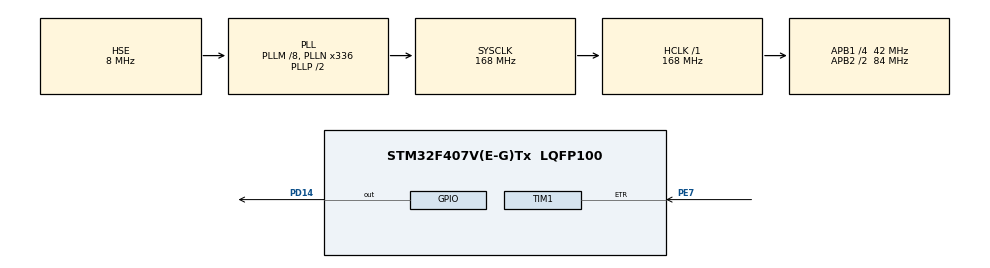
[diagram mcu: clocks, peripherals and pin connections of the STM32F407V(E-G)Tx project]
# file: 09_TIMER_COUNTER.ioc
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Mcu.Family=STM32F4
Mcu.Name=STM32F407V(E-G)Tx
Mcu.Package=LQFP100
NVIC.PriorityGroup=NVIC_PRIORITYGROUP_0
NVIC.TIM1_UP_TIM10_IRQn=true\:0\:0\:false\:false\:true\:true\:true
NVIC.TIM2_IRQn=true\:0\:0\:false\:false\:true\:false\:true
NVIC.TimeBase=TIM2_IRQn
NVIC.TimeBaseIP=TIM2
PA13.Mode=Serial_Wire
PA13.Signal=SYS_JTMS-SWDIO
PA14.Mode=Serial_Wire
PA14.Signal=SYS_JTCK-SWCLK
PD14.Signal=GPIO_Output
PE7.Signal=S_TIM1_ETR
PH0-OSC_IN.Mode=HSE-External-Oscillator
PH0-OSC_IN.Signal=RCC_OSC_IN
PH1-OSC_OUT.Mode=HSE-External-Oscillator
PH1-OSC_OUT.Signal=RCC_OSC_OUT
ProjectManager.HeapSize=0x200
ProjectManager.StackSize=0x400
ProjectManager.TargetToolchain=STM32CubeIDE
RCC.48MHZClocksFreq_Value=48000000
RCC.AHBFreq_Value=168000000
RCC.APB1CLKDivider=RCC_HCLK_DIV4
RCC.APB1Freq_Value=42000000
RCC.APB1TimFreq_Value=84000000
RCC.APB2CLKDivider=RCC_HCLK_DIV2
RCC.APB2Freq_Value=84000000
RCC.APB2TimFreq_Value=168000000
RCC.CortexFreq_Value=168000000
RCC.HCLKFreq_Value=168000000
RCC.HSE_VALUE=8000000
RCC.HSI_VALUE=16000000
RCC.PLLM=8
RCC.PLLN=336
RCC.PLLQ=7
RCC.PLLSourceVirtual=RCC_PLLSOURCE_HSE
RCC.SYSCLKFreq_VALUE=168000000
RCC.SYSCLKSource=RCC_SYSCLKSOURCE_PLLCLK
RCC.VCOOutputFreq_Value=336000000
SH.S_TIM1_ETR.0=TIM1_ETR,ClockSourceETR_Mode2
TIM1.Period=5
VP_SYS_VS_tim2.Mode=TIM2
board=STM32F407G-DISC1

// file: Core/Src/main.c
/* USER CODE BEGIN Header */
/**
  ******************************************************************************
  * @file           : main.c
  * @brief          : Main program body
  ******************************************************************************
  * @attention
  *
  * <h2><center>&copy; Copyright (c) 2021 STMicroelectronics.
  * All rights reserved.</center></h2>
  *
  * This software component is licensed by ST under Ultimate Liberty license
  * SLA0044, the "License"; You may not use this file except in compliance with
  * the License. You may obtain a copy of the License at:
  *                             www.st.com/SLA0044
  *
  ******************************************************************************
  */
/* USER CODE END Header */
#include "main.h"

TIM_HandleTypeDef htim1;

void SystemClock_Config(void);
static void MX_GPIO_Init(void);
static void MX_TIM1_Init(void);

int main(void)
{

  /* MCU Configuration--------------------------------------------------------*/

  /* Reset of all peripherals, Initializes the Flash interface and the Systick. */
  HAL_Init();

  /* Configure the system clock */
  SystemClock_Config();

  /* Initialize all configured peripherals */
  MX_GPIO_Init();
  MX_TIM1_Init();
  /* USER CODE BEGIN 2 */
  HAL_TIM_Base_Start_IT(&htim1);
  /* USER CODE END 2 */

  /* Infinite loop */
  while (1)
  {

  }
}

void SystemClock_Config(void)
{
  RCC_OscInitTypeDef RCC_OscInitStruct = {0};
  RCC_ClkInitTypeDef RCC_ClkInitStruct = {0};

  /** Configure the main internal regulator output voltage
  */
  __HAL_RCC_PWR_CLK_ENABLE();
  __HAL_PWR_VOLTAGESCALING_CONFIG(PWR_REGULATOR_VOLTAGE_SCALE1);
  /** Initializes the RCC Oscillators according to the specified parameters
  * in the RCC_OscInitTypeDef structure.
  */
  RCC_OscInitStruct.OscillatorType = RCC_OSCILLATORTYPE_HSE;
  RCC_OscInitStruct.HSEState = RCC_HSE_ON;
  RCC_OscInitStruct.PLL.PLLState = RCC_PLL_ON;
  RCC_OscInitStruct.PLL.PLLSource = RCC_PLLSOURCE_HSE;
  RCC_OscInitStruct.PLL.PLLM = 8;
  RCC_OscInitStruct.PLL.PLLN = 336;
  RCC_OscInitStruct.PLL.PLLP = RCC_PLLP_DIV2;
  RCC_OscInitStruct.PLL.PLLQ = 7;
  if (HAL_RCC_OscConfig(&RCC_OscInitStruct) != HAL_OK)
  {
    Error_Handler();
  }
  /** Initializes the CPU, AHB and APB buses clocks
  */
  RCC_ClkInitStruct.ClockType = RCC_CLOCKTYPE_HCLK|RCC_CLOCKTYPE_SYSCLK
                              |RCC_CLOCKTYPE_PCLK1|RCC_CLOCKTYPE_PCLK2;
  RCC_ClkInitStruct.SYSCLKSource = RCC_SYSCLKSOURCE_PLLCLK;
  RCC_ClkInitStruct.AHBCLKDivider = RCC_SYSCLK_DIV1;
  RCC_ClkInitStruct.APB1CLKDivider = RCC_HCLK_DIV4;
  RCC_ClkInitStruct.APB2CLKDivider = RCC_HCLK_DIV2;

  if (HAL_RCC_ClockConfig(&RCC_ClkInitStruct, FLASH_LATENCY_5) != HAL_OK)
  {
    Error_Handler();
  }
}

static void MX_TIM1_Init(void)
{

  TIM_ClockConfigTypeDef sClockSourceConfig = {0};
  TIM_MasterConfigTypeDef sMasterConfig = {0};

  htim1.Instance = TIM1;
  htim1.Init.Prescaler = 0;
  htim1.Init.CounterMode = TIM_COUNTERMODE_UP;
  htim1.Init.Period = 5;
  htim1.Init.ClockDivision = TIM_CLOCKDIVISION_DIV1;
  htim1.Init.RepetitionCounter = 0;
  htim1.Init.AutoReloadPreload = TIM_AUTORELOAD_PRELOAD_DISABLE;
  if (HAL_TIM_Base_Init(&htim1) != HAL_OK)
  {
    Error_Handler();
  }
  sClockSourceConfig.ClockSource = TIM_CLOCKSOURCE_ETRMODE2;
  sClockSourceConfig.ClockPolarity = TIM_CLOCKPOLARITY_NONINVERTED;
  sClockSourceConfig.ClockPrescaler = TIM_CLOCKPRESCALER_DIV1;
  sClockSourceConfig.ClockFilter = 0;
  if (HAL_TIM_ConfigClockSource(&htim1, &sClockSourceConfig) != HAL_OK)
  {
    Error_Handler();
  }
  sMasterConfig.MasterOutputTrigger = TIM_TRGO_RESET;
  sMasterConfig.MasterSlaveMode = TIM_MASTERSLAVEMODE_DISABLE;
  if (HAL_TIMEx_MasterConfigSynchronization(&htim1, &sMasterConfig) != HAL_OK)
  {
    Error_Handler();
  }

}

static void MX_GPIO_Init(void)
{
  GPIO_InitTypeDef GPIO_InitStruct = {0};

  /* GPIO Ports Clock Enable */
  __HAL_RCC_GPIOH_CLK_ENABLE();
  __HAL_RCC_GPIOE_CLK_ENABLE();
  __HAL_RCC_GPIOD_CLK_ENABLE();
  __HAL_RCC_GPIOA_CLK_ENABLE();

  /*Configure GPIO pin Output Level */
  HAL_GPIO_WritePin(GPIOD, GPIO_PIN_14, GPIO_PIN_RESET);

  /*Configure GPIO pin : PD14 */
  GPIO_InitStruct.Pin = GPIO_PIN_14;
  GPIO_InitStruct.Mode = GPIO_MODE_OUTPUT_PP;
  GPIO_InitStruct.Pull = GPIO_NOPULL;
  GPIO_InitStruct.Speed = GPIO_SPEED_FREQ_LOW;
  HAL_GPIO_Init(GPIOD, &GPIO_InitStruct);

}

void HAL_TIM_PeriodElapsedCallback(TIM_HandleTypeDef *htim)
{
  if (htim->Instance == TIM2) {
    HAL_IncTick();
  }
  /* USER CODE BEGIN Callback 1 */
  HAL_GPIO_TogglePin(GPIOD,GPIO_PIN_14);
  /* USER CODE END Callback 1 */
}

void Error_Handler(void)
{
  __disable_irq();
  while (1)
  {
  }
}

/************************ (C) COPYRIGHT STMicroelectronics *****END OF FILE****/
